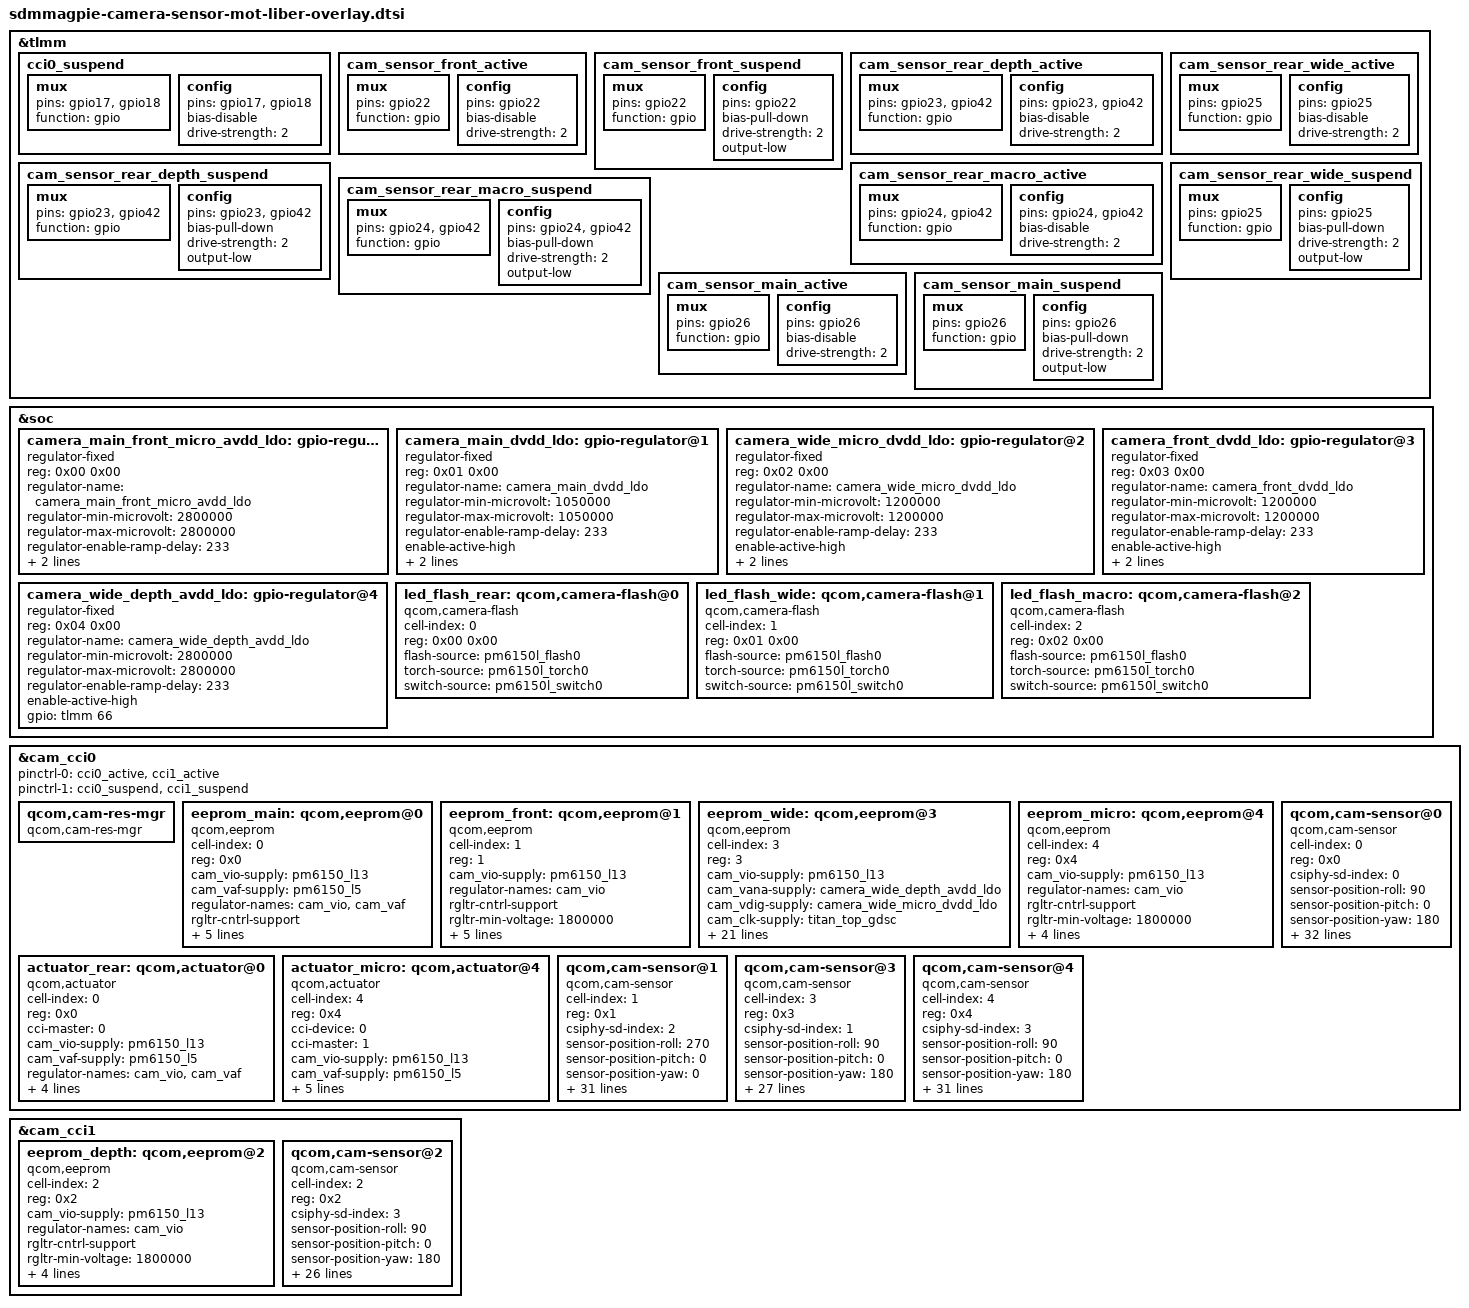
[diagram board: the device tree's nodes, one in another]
/*
 * Copyright (c) 2018-2019, The Linux Foundation. All rights reserved.
 *
 * This program is free software; you can redistribute it and/or modify
 * it under the terms of the GNU General Public License version 2 and
 * only version 2 as published by the Free Software Foundation.
 *
 * This program is distributed in the hope that it will be useful,
 * but WITHOUT ANY WARRANTY; without even the implied warranty of
 * MERCHANTABILITY or FITNESS FOR A PARTICULAR PURPOSE.  See the
 * GNU General Public License for more details.
 */

&tlmm {
	/delete-node/ cci0_suspend;

	cci0_suspend: cci0_suspend {
		mux {
			/* CLK, DATA */
			pins = "gpio17","gpio18";
			function = "gpio";
		};

		config {
			pins = "gpio17","gpio18";
			bias-disable; /* NO PULL */
			drive-strength = <2>; /* 2 MA */
		};
	};

	cam_sensor_front_active: cam_sensor_front_active {
		/* RESET  */
		mux {
			pins = "gpio22";
			function = "gpio";
		};

		config {
			pins = "gpio22";
			bias-disable; /* No PULL */
			drive-strength = <2>; /* 2 MA */
		};
	};

	cam_sensor_front_suspend: cam_sensor_front_suspend {
		/* RESET */
		mux {
			pins = "gpio22";
			function = "gpio";
		};

		config {
			pins = "gpio22";
			bias-pull-down; /* PULL DOWN */
			drive-strength = <2>; /* 2 MA */
			output-low;
		};
	};

	cam_sensor_rear_depth_active: cam_sensor_rear_depth_active {
		/* RESET  */
		mux {
			pins = "gpio23", "gpio42";
			function = "gpio";
		};

		config {
			pins = "gpio23", "gpio42";
			bias-disable; /* No PULL */
			drive-strength = <2>; /* 2 MA */
		};
	};

	cam_sensor_rear_depth_suspend: cam_sensor_rear_depth_suspend {
		/* RESET */
		mux {
			pins = "gpio23", "gpio42";
			function = "gpio";
		};

		config {
			pins = "gpio23", "gpio42";
			bias-pull-down; /* PULL DOWN */
			drive-strength = <2>; /* 2 MA */
			output-low;
		};
	};

	cam_sensor_rear_macro_active: cam_sensor_rear_macro_active {
		/* RESET  */
		mux {
			pins = "gpio24", "gpio42";
			function = "gpio";
		};

		config {
			pins = "gpio24", "gpio42";
			bias-disable; /* No PULL */
			drive-strength = <2>; /* 2 MA */
		};
	};

	cam_sensor_rear_macro_suspend: cam_sensor_rear_macro_suspend {
		/* RESET */
		mux {
			pins = "gpio24", "gpio42";
			function = "gpio";
		};

		config {
			pins = "gpio24", "gpio42";
			bias-pull-down; /* PULL DOWN */
			drive-strength = <2>; /* 2 MA */
			output-low;
		};
	};

	cam_sensor_rear_wide_active: cam_sensor_rear_wide_active {
		/* RESET  */
		mux {
			pins = "gpio25";
			function = "gpio";
		};

		config {
			pins = "gpio25";
			bias-disable; /* No PULL */
			drive-strength = <2>; /* 2 MA */
		};
	};

	cam_sensor_rear_wide_suspend: cam_sensor_rear_wide_suspend {
		/* RESET */
		mux {
			pins = "gpio25";
			function = "gpio";
		};

		config {
			pins = "gpio25";
			bias-pull-down; /* PULL DOWN */
			drive-strength = <2>; /* 2 MA */
			output-low;
		};
	};

	cam_sensor_main_active: cam_sensor_main_active {
		/* RESET  */
		mux {
			pins = "gpio26";
			function = "gpio";
		};

		config {
			pins = "gpio26";
			bias-disable; /* No PULL */
			drive-strength = <2>; /* 2 MA */
		};
	};

	cam_sensor_main_suspend: cam_sensor_main_suspend {
		/* RESET */
		mux {
			pins = "gpio26";
			function = "gpio";
		};

		config {
			pins = "gpio26";
			bias-pull-down; /* PULL DOWN */
			drive-strength = <2>; /* 2 MA */
			output-low;
		};
	};
};

&soc {
	camera_main_front_micro_avdd_ldo: gpio-regulator@0 {
		compatible = "regulator-fixed";
		reg = <0x00 0x00>;
		regulator-name = "camera_main_front_micro_avdd_ldo";
		regulator-min-microvolt = <2800000>;
		regulator-max-microvolt = <2800000>;
		regulator-enable-ramp-delay = <233>;
		enable-active-high;
		gpio = <&tlmm 63 0>;
	};

	camera_main_dvdd_ldo: gpio-regulator@1 {
		compatible = "regulator-fixed";
		reg = <0x01 0x00>;
		regulator-name = "camera_main_dvdd_ldo";
		regulator-min-microvolt = <1050000>;
		regulator-max-microvolt = <1050000>;
		regulator-enable-ramp-delay = <233>;
		enable-active-high;
		gpio = <&tlmm 64 0>;
		vin-supply = <&pm6150l_s8>;
	};

	camera_wide_micro_dvdd_ldo: gpio-regulator@2 {
		compatible = "regulator-fixed";
		reg = <0x02 0x00>;
		regulator-name = "camera_wide_micro_dvdd_ldo";
		regulator-min-microvolt = <1200000>;
		regulator-max-microvolt = <1200000>;
		regulator-enable-ramp-delay = <233>;
		enable-active-high;
		gpio = <&tlmm 65 0>;
		vin-supply = <&pm6150l_s8>;
	};

	camera_front_dvdd_ldo: gpio-regulator@3 {
		compatible = "regulator-fixed";
		reg = <0x03 0x00>;
		regulator-name = "camera_front_dvdd_ldo";
		regulator-min-microvolt = <1200000>;
		regulator-max-microvolt = <1200000>;
		regulator-enable-ramp-delay = <233>;
		enable-active-high;
		gpio = <&tlmm 67 0>;
		vin-supply = <&pm6150l_s8>;
	};

	camera_wide_depth_avdd_ldo: gpio-regulator@4 {
		compatible = "regulator-fixed";
		reg = <0x04 0x00>;
		regulator-name = "camera_wide_depth_avdd_ldo";
		regulator-min-microvolt = <2800000>;
		regulator-max-microvolt = <2800000>;
		regulator-enable-ramp-delay = <233>;
		enable-active-high;
		gpio = <&tlmm 66 0>;
	};

	led_flash_rear: qcom,camera-flash@0 {
		cell-index = <0>;
		reg = <0x00 0x00>;
		compatible = "qcom,camera-flash";
		flash-source = <&pm6150l_flash0>;
		torch-source = <&pm6150l_torch0>;
		switch-source = <&pm6150l_switch0>;
		status = "ok";
	};

	led_flash_wide: qcom,camera-flash@1 {
		cell-index = <1>;
		reg = <0x01 0x00>;
		compatible = "qcom,camera-flash";
		flash-source = <&pm6150l_flash0>;
		torch-source = <&pm6150l_torch0>;
		switch-source = <&pm6150l_switch0>;
		status = "ok";
	};


	led_flash_macro: qcom,camera-flash@2 {
		cell-index = <2>;
		reg = <0x02 0x00>;
		compatible = "qcom,camera-flash";
		flash-source = <&pm6150l_flash0>;
		torch-source = <&pm6150l_torch0>;
		switch-source = <&pm6150l_switch0>;
		status = "ok";
	};

};

&cam_cci0 {
	pinctrl-0 = <&cci0_active &cci1_active>;
	pinctrl-1 = <&cci0_suspend &cci1_suspend>;

	qcom,cam-res-mgr {
		compatible = "qcom,cam-res-mgr";
		status = "ok";
	};

	eeprom_main: qcom,eeprom@0 {
		cell-index = <0>;
		reg = <0x0>;
		compatible = "qcom,eeprom";
		cam_vio-supply = <&pm6150_l13>;
		cam_vaf-supply = <&pm6150_l5>;
		regulator-names = "cam_vio","cam_vaf";
		rgltr-cntrl-support;
		rgltr-min-voltage = <1800000 2800000>;
		rgltr-max-voltage = <1800000 2800000>;
		rgltr-load-current = <0 0>;
		cci-device = <0>;
		cci-master = <0>;
	};

	eeprom_front: qcom,eeprom@1 {
		cell-index = <1>;
		reg = <1>;
		compatible = "qcom,eeprom";
		cam_vio-supply = <&pm6150_l13>;
		regulator-names = "cam_vio";
		rgltr-cntrl-support;
		rgltr-min-voltage = <1800000>;
		rgltr-max-voltage = <1800000>;
		rgltr-load-current = <0>;
		sensor-mode = <1>;
		cci-device = <0>;
		cci-master = <0>;
		status = "ok";
	};

	eeprom_wide: qcom,eeprom@3 {
		cell-index = <3>;
		reg = <3>;
		compatible = "qcom,eeprom";
		cam_vio-supply = <&pm6150_l13>;
		cam_vana-supply = <&camera_wide_depth_avdd_ldo>;
		cam_vdig-supply = <&camera_wide_micro_dvdd_ldo>;
		cam_clk-supply = <&titan_top_gdsc>;
		regulator-names = "cam_vio", "cam_vana", "cam_vdig", "cam_clk";
		rgltr-cntrl-support;
		rgltr-min-voltage = <1800000 2800000 1200000 0>;
		rgltr-max-voltage = <1800000 2800000 1200000 0>;
		rgltr-load-current = <0 80000 105000 0>;
		gpio-no-mux = <0>;
		pinctrl-names = "cam_default", "cam_suspend";
		pinctrl-0 = <&cam_sensor_mclk1_active
				&cam_sensor_rear_wide_active>;
		pinctrl-1 = <&cam_sensor_mclk1_suspend
				&cam_sensor_rear_wide_suspend>;
		gpios = <&tlmm 14 0>,
			<&tlmm 25 0>;
		gpio-reset = <1>;
		gpio-req-tbl-num = <0 1>;
		gpio-req-tbl-flags = <1 0>;
		gpio-req-tbl-label = "CAMIF_MCLK1", "CAM_RESET0";
		cci-device = <0>;
		cci-master = <1>;
		status = "ok";
		clocks = <&clock_camcc CAM_CC_MCLK1_CLK>;
		clock-names = "cam_clk";
		clock-cntl-level = "turbo";
		clock-rates = <24000000>;
	};

	eeprom_micro: qcom,eeprom@4 {
		cell-index = <4>;
		reg = <0x4>;
		compatible = "qcom,eeprom";
		cam_vio-supply = <&pm6150_l13>;
		regulator-names = "cam_vio";
		rgltr-cntrl-support;
		rgltr-min-voltage = <1800000>;
		rgltr-max-voltage = <1800000>;
		rgltr-load-current = <0>;
		cci-device = <0>;
		cci-master = <1>;
	};

	actuator_rear: qcom,actuator@0 {
		cell-index = <0>;
		reg = <0x0>;
		compatible = "qcom,actuator";
		cci-master = <0>;
		cam_vio-supply = <&pm6150_l13>;
		cam_vaf-supply = <&pm6150_l5>;
		regulator-names = "cam_vio","cam_vaf";
		rgltr-cntrl-support;
		rgltr-min-voltage = <1800000 2800000>;
		rgltr-max-voltage = <1800000 2800000>;
		rgltr-load-current = <0 0>;
	};

	actuator_micro: qcom,actuator@4 {
		cell-index = <4>;
		reg = <0x4>;
		compatible = "qcom,actuator";
		cci-device = <0>;
		cci-master = <1>;
		cam_vio-supply = <&pm6150_l13>;
		cam_vaf-supply = <&pm6150_l5>;
		regulator-names = "cam_vio","cam_vaf";
		rgltr-cntrl-support;
		rgltr-min-voltage = <1800000 2800000>;
		rgltr-max-voltage = <1800000 2800000>;
		rgltr-load-current = <0 0>;
	};

	qcom,cam-sensor@0 {
		cell-index = <0>;
		compatible = "qcom,cam-sensor";
		reg = <0x0>;
		csiphy-sd-index = <0>;
		sensor-position-roll = <90>;
		sensor-position-pitch = <0>;
		sensor-position-yaw = <180>;
		led-flash-src = <&led_flash_rear>;
		actuator-src = <&actuator_rear>;
		eeprom-src = <&eeprom_main>;
		cam_vio-supply = <&pm6150_l13>;
		cam_vana-supply = <&camera_main_front_micro_avdd_ldo>;
		cam_vdig-supply = <&camera_main_dvdd_ldo>;
		cam_vaf-supply = <&pm6150_l5>;
		cam_clk-supply = <&titan_top_gdsc>;
		regulator-names = "cam_vio", "cam_vana", "cam_vdig", "cam_vaf", "cam_clk";
		rgltr-cntrl-support;
		rgltr-min-voltage = <1800000 2800000 1050000 2800000 0>;
		rgltr-max-voltage = <1800000 2800000 1050000 2800000 0>;
		rgltr-load-current = <0 80000 105000 80000 0>;
		gpio-no-mux = <0>;
		pinctrl-names = "cam_default", "cam_suspend";
		pinctrl-0 = <&cam_sensor_mclk2_active
				&cam_sensor_main_active>;
		pinctrl-1 = <&cam_sensor_mclk2_suspend
				&cam_sensor_main_suspend>;
		gpios = <&tlmm 15 0>,
			<&tlmm 26 0>;
		gpio-reset = <1>;
		gpio-req-tbl-num = <0 1>;
		gpio-req-tbl-flags = <1 0>;
		gpio-req-tbl-label = "CAMIF_MCLK2", "CAM_RESET0";
		cci-device = <0>;
		cci-master = <0>;
		status = "ok";
		clocks = <&clock_camcc CAM_CC_MCLK2_CLK>;
		clock-names = "cam_clk";
		clock-cntl-level = "turbo";
		clock-rates = <24000000>;
	};

	qcom,cam-sensor@1 {
		cell-index = <1>;
		compatible = "qcom,cam-sensor";
		reg = <0x1>;
		csiphy-sd-index = <2>;
		sensor-position-roll = <270>;
		sensor-position-pitch = <0>;
		sensor-position-yaw = <0>;
		eeprom-src = <&eeprom_front>;
		cam_vio-supply = <&pm6150_l13>;
		cam_vana-supply = <&camera_main_front_micro_avdd_ldo>;
		cam_vdig-supply = <&camera_front_dvdd_ldo>;
		cam_vaf-supply = <&pm6150_l5>;
		cam_clk-supply = <&titan_top_gdsc>;
		regulator-names = "cam_vio", "cam_vana", "cam_vdig", "cam_vaf", "cam_clk";
		rgltr-cntrl-support;
		rgltr-min-voltage = <1800000 2800000 1200000 2800000 0>;
		rgltr-max-voltage = <1800000 2800000 1200000 2800000 0>;
		rgltr-load-current = <0 80000 105000 80000 0>;
		gpio-no-mux = <0>;
		pinctrl-names = "cam_default", "cam_suspend";
		pinctrl-0 = <&cam_sensor_mclk0_active
				&cam_sensor_front_active>;
		pinctrl-1 = <&cam_sensor_mclk0_suspend
				&cam_sensor_front_suspend>;
		gpios = <&tlmm 13 0>,
			<&tlmm 22 0>;
		gpio-reset = <1>;
		gpio-req-tbl-num = <0 1>;
		gpio-req-tbl-flags = <1 0>;
		gpio-req-tbl-label = "CAMIF_MCLK0", "CAM_RESET0";
		sensor-mode = <1>;
		cci-device = <0>;
		cci-master = <0>;
		status = "ok";
		clocks = <&clock_camcc CAM_CC_MCLK0_CLK>;
		clock-names = "cam_clk";
		clock-cntl-level = "turbo";
		clock-rates = <24000000>;
	};

	qcom,cam-sensor@3 {
		cell-index = <3>;
		compatible = "qcom,cam-sensor";
		reg = <0x3>;
		csiphy-sd-index = <1>;
		sensor-position-roll = <90>;
		sensor-position-pitch = <0>;
		sensor-position-yaw = <180>;
		led-flash-src = <&led_flash_wide>;
		cam_vio-supply = <&pm6150_l13>;
		cam_vana-supply = <&camera_wide_depth_avdd_ldo>;
		cam_vdig-supply = <&camera_wide_micro_dvdd_ldo>;
		cam_clk-supply = <&titan_top_gdsc>;
		eeprom-src = <&eeprom_wide>;
		regulator-names = "cam_vio", "cam_vana", "cam_vdig", "cam_clk";
		rgltr-cntrl-support;
		rgltr-min-voltage = <1800000 2800000 1200000 0>;
		rgltr-max-voltage = <1800000 2800000 1200000 0>;
		rgltr-load-current = <0 80000 105000 0>;
		gpio-no-mux = <0>;
		pinctrl-names = "cam_default", "cam_suspend";
		pinctrl-0 = <&cam_sensor_mclk1_active
				&cam_sensor_rear_wide_active>;
		pinctrl-1 = <&cam_sensor_mclk1_suspend
				&cam_sensor_rear_wide_suspend>;
		gpios = <&tlmm 14 0>,
			<&tlmm 25 0>;
		gpio-reset = <1>;
		gpio-req-tbl-num = <0 1>;
		gpio-req-tbl-flags = <1 0>;
		gpio-req-tbl-label = "CAMIF_MCLK1", "CAM_RESET0";
		cci-device = <0>;
		cci-master = <1>;
		status = "ok";
		clocks = <&clock_camcc CAM_CC_MCLK1_CLK>;
		clock-names = "cam_clk";
		clock-cntl-level = "turbo";
		clock-rates = <24000000>;
	};

	qcom,cam-sensor@4 {
		cell-index = <4>;
		compatible = "qcom,cam-sensor";
		reg = <0x4>;
		csiphy-sd-index = <3>;
		sensor-position-roll = <90>;
		sensor-position-pitch = <0>;
		sensor-position-yaw = <180>;
		led-flash-src = <&led_flash_macro>;
		actuator-src = <&actuator_micro>;
		eeprom-src = <&eeprom_micro>;
		cam_vio-supply = <&pm6150_l13>;
		cam_vana-supply = <&camera_main_front_micro_avdd_ldo>;
		cam_vdig-supply = <&camera_wide_micro_dvdd_ldo>;
		cam_clk-supply = <&titan_top_gdsc>;
		regulator-names = "cam_vio", "cam_vana", "cam_vdig", "cam_clk";
		rgltr-cntrl-support;
		rgltr-min-voltage = <1800000 2800000 1200000 0>;
		rgltr-max-voltage = <1800000 2800000 1200000 0>;
		rgltr-load-current = <0 80000 105000 0>;
		gpio-no-mux = <0>;
		pinctrl-names = "cam_default", "cam_suspend";
		pinctrl-0 = <&cam_sensor_mclk3_active
				&cam_sensor_rear_macro_active>;
		pinctrl-1 = <&cam_sensor_mclk3_suspend
				&cam_sensor_rear_macro_suspend>;
		gpios = <&tlmm 16 0>,
			<&tlmm 24 0>,
			<&tlmm 42 0>;
		gpio-reset = <1>;
		gpio-custom1= <2>;
		gpio-req-tbl-num = <0 1 2>;
		gpio-req-tbl-flags = <1 0 0>;
		gpio-req-tbl-label = "CAMIF_MCLK3", "CAM_RESET3", "CAM_SW3";
		cci-device = <0>;
		cci-master = <1>;
		status = "ok";
		clocks = <&clock_camcc CAM_CC_MCLK3_CLK>;
		clock-names = "cam_clk";
		clock-cntl-level = "turbo";
		clock-rates = <24000000>;
	};
};

&cam_cci1 {
	eeprom_depth: qcom,eeprom@2 {
		cell-index = <2>;
		reg = <0x2>;
		compatible = "qcom,eeprom";
		cam_vio-supply = <&pm6150_l13>;
		regulator-names = "cam_vio";
		rgltr-cntrl-support;
		rgltr-min-voltage = <1800000>;
		rgltr-max-voltage = <1800000>;
		rgltr-load-current = <0>;
		cci-device = <1>;
		cci-master = <0>;
	};

	qcom,cam-sensor@2 {
		cell-index = <2>;
		compatible = "qcom,cam-sensor";
		reg = <0x2>;
		csiphy-sd-index = <3>;
		sensor-position-roll = <90>;
		sensor-position-pitch = <0>;
		sensor-position-yaw = <180>;
		eeprom-src = <&eeprom_depth>;
		cam_vio-supply = <&pm6150_l13>;
		cam_vana-supply = <&camera_wide_depth_avdd_ldo>;
		cam_clk-supply = <&titan_top_gdsc>;
		regulator-names = "cam_vio", "cam_vana", "cam_clk";
		rgltr-cntrl-support;
		rgltr-min-voltage = <1800000 2800000 0>;
		rgltr-max-voltage = <1800000 2800000 0>;
		rgltr-load-current = <0 80000 0>;
		gpio-no-mux = <0>;
		pinctrl-names = "cam_default", "cam_suspend";
		pinctrl-0 = <&cam_sensor_mclk3_active
				&cam_sensor_rear_depth_active>;
		pinctrl-1 = <&cam_sensor_mclk3_suspend
				&cam_sensor_rear_depth_suspend>;
		gpios = <&tlmm 16 0>,
			<&tlmm 23 0>,
			<&tlmm 42 0>;
		gpio-reset = <1>;
		gpio-custom1= <2>;
		gpio-req-tbl-num = <0 1 2>;
		gpio-req-tbl-flags = <1 0 0>;
		gpio-req-tbl-label = "CAMIF_MCLK3", "CAM_RESET3", "CAM_SW3";
		cci-device = <1>;
		cci-master = <0>;
		status = "ok";
		clocks = <&clock_camcc CAM_CC_MCLK3_CLK>;
		clock-names = "cam_clk";
		clock-cntl-level = "turbo";
		clock-rates = <24000000>;
	};
};

